AUTOSAR XML (schema 4-2-2)
package /ASW_COM_STD_Pkg
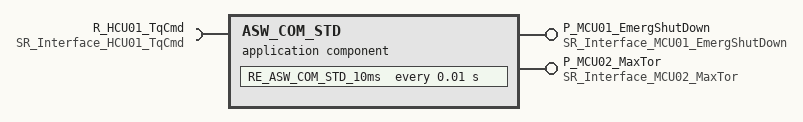
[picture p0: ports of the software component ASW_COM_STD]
  application sw component type ASW_COM_STD
    provide port P_MCU01_EmergShutDown: provided-interface=SR_Interface_MCU01_EmergShutDown
    provide port P_MCU02_MaxTor: provided-interface=SR_Interface_MCU02_MaxTor
    require port R_HCU01_TqCmd: nonqueued-receiver-com-spec{data-element=DE_HCU01_TqCmd, alive-timeout=0.3}, required-interface=SR_Interface_HCU01_TqCmd
    behavior IB_ASW_COM_STD
      timing event TE_RE_ASW_COM_STD_10ms: start-on-event=RE_ASW_COM_STD_10ms, period=0.01
      runnable RE_ASW_COM_STD_10ms
        data-read-access-points:
          access VA_R_HCU01_TqCmd: accessed-variable=R_HCU01_TqCmd.DE_HCU01_TqCmd
        data-write-access-points:
          access VA_P_MCU01_EmergShutDown: accessed-variable=P_MCU01_EmergShutDown.DE_MCU01_EmergShutDown
          access VA_P_MCU02_MaxTor: accessed-variable=P_MCU02_MaxTor.DE_MCU02_MaxTor
